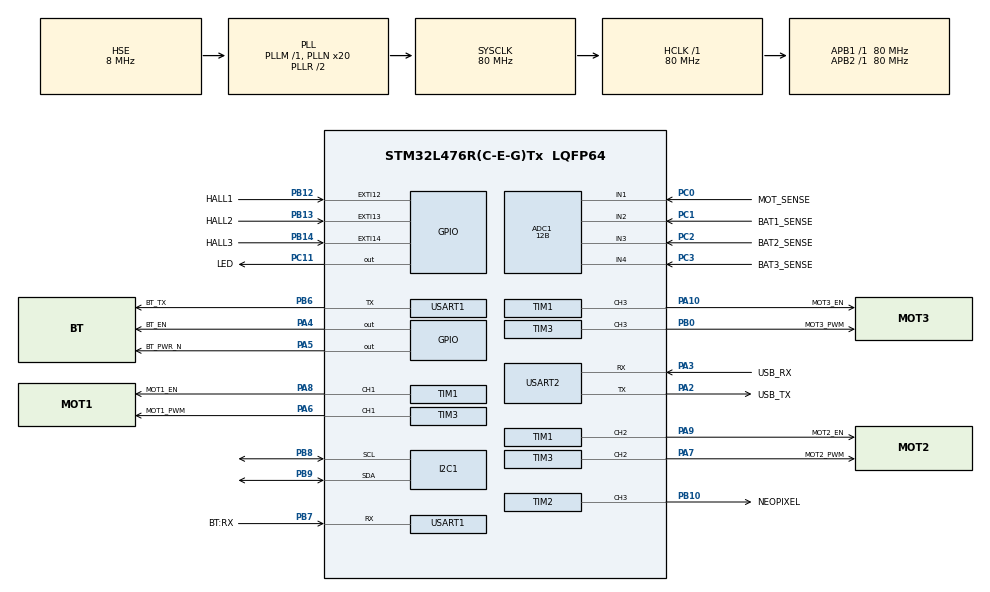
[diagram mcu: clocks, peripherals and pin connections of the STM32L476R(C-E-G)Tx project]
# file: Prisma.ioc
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ADC1.Channel-0\#ChannelRegularConversion=ADC_CHANNEL_1
ADC1.Channel-1\#ChannelRegularConversion=ADC_CHANNEL_2
ADC1.Channel-2\#ChannelRegularConversion=ADC_CHANNEL_3
ADC1.Channel-3\#ChannelRegularConversion=ADC_CHANNEL_4
ADC1.ClockPrescaler=ADC_CLOCK_ASYNC_DIV128
ADC1.ContinuousConvMode=ENABLE
ADC1.DMAContinuousRequests=DISABLE
ADC1.EOCSelection=ADC_EOC_SEQ_CONV
ADC1.NbrOfConversion=4
ADC1.NbrOfConversionFlag=1
ADC1.OffsetNumber-0\#ChannelRegularConversion=ADC_OFFSET_NONE
ADC1.OffsetNumber-1\#ChannelRegularConversion=ADC_OFFSET_NONE
ADC1.OffsetNumber-2\#ChannelRegularConversion=ADC_OFFSET_NONE
ADC1.OffsetNumber-3\#ChannelRegularConversion=ADC_OFFSET_NONE
ADC1.Rank-0\#ChannelRegularConversion=1
ADC1.Rank-1\#ChannelRegularConversion=2
ADC1.Rank-2\#ChannelRegularConversion=3
ADC1.Rank-3\#ChannelRegularConversion=4
ADC1.Resolution=ADC_RESOLUTION_12B
ADC1.SamplingTime-0\#ChannelRegularConversion=ADC_SAMPLETIME_2CYCLES_5
ADC1.SamplingTime-1\#ChannelRegularConversion=ADC_SAMPLETIME_2CYCLES_5
ADC1.SamplingTime-2\#ChannelRegularConversion=ADC_SAMPLETIME_2CYCLES_5
ADC1.SamplingTime-3\#ChannelRegularConversion=ADC_SAMPLETIME_2CYCLES_5
ADC1.master=1
Dma.ADC1.0.Direction=DMA_PERIPH_TO_MEMORY
Dma.ADC1.0.Instance=DMA2_Channel3
Dma.ADC1.0.MemDataAlignment=DMA_MDATAALIGN_HALFWORD
Dma.ADC1.0.MemInc=DMA_MINC_ENABLE
Dma.ADC1.0.Mode=DMA_CIRCULAR
Dma.ADC1.0.PeriphDataAlignment=DMA_PDATAALIGN_HALFWORD
Dma.ADC1.0.PeriphInc=DMA_PINC_DISABLE
Dma.ADC1.0.Priority=DMA_PRIORITY_LOW
Dma.Request0=ADC1
Dma.Request1=TIM2_CH3
Dma.TIM2_CH3.1.Direction=DMA_MEMORY_TO_PERIPH
Dma.TIM2_CH3.1.Instance=DMA1_Channel1
Dma.TIM2_CH3.1.MemDataAlignment=DMA_MDATAALIGN_HALFWORD
Dma.TIM2_CH3.1.MemInc=DMA_MINC_ENABLE
Dma.TIM2_CH3.1.Mode=DMA_NORMAL
Dma.TIM2_CH3.1.PeriphDataAlignment=DMA_PDATAALIGN_WORD
Dma.TIM2_CH3.1.PeriphInc=DMA_PINC_DISABLE
Dma.TIM2_CH3.1.Priority=DMA_PRIORITY_LOW
I2C1.Timing=0x10909CEC
Mcu.Family=STM32L4
Mcu.Name=STM32L476R(C-E-G)Tx
Mcu.Package=LQFP64
NVIC.DMA1_Channel1_IRQn=true\:0\:0\:false\:false\:true\:false\:true\:true
NVIC.DMA2_Channel3_IRQn=true\:0\:0\:false\:false\:true\:false\:true\:true
NVIC.EXTI15_10_IRQn=true\:2\:0\:true\:false\:false\:true\:false\:true
NVIC.PriorityGroup=NVIC_PRIORITYGROUP_4
NVIC.TIM4_IRQn=true\:0\:0\:false\:false\:false\:true\:false\:true
NVIC.TIM7_IRQn=true\:0\:0\:false\:false\:false\:true\:false\:true
NVIC.USART1_IRQn=true\:0\:0\:false\:false\:false\:true\:false\:true
NVIC.USART2_IRQn=true\:0\:0\:false\:false\:false\:true\:false\:true
PA10.GPIO_Label=MOT3_EN
PA10.GPIO_PuPd=GPIO_PULLDOWN
PA10.Signal=S_TIM1_CH3
PA13\ (JTMS-SWDIO).Mode=Serial_Wire
PA13\ (JTMS-SWDIO).Signal=SYS_JTMS-SWDIO
PA14\ (JTCK-SWCLK).Mode=Serial_Wire
PA14\ (JTCK-SWCLK).Signal=SYS_JTCK-SWCLK
PA2.GPIO_Label=USB_TX
PA2.Mode=Asynchronous
PA2.Signal=USART2_TX
PA3.GPIO_Label=USB_RX
PA3.Mode=Asynchronous
PA3.Signal=USART2_RX
PA4.GPIO_Label=BT_EN
PA4.Signal=GPIO_Output
PA5.GPIO_Label=BT_PWR_N
PA5.PinState=GPIO_PIN_SET
PA5.Signal=GPIO_Output
PA6.GPIO_Label=MOT1_PWM
PA6.GPIO_PuPd=GPIO_PULLDOWN
PA6.Signal=S_TIM3_CH1
PA7.GPIO_Label=MOT2_PWM
PA7.GPIO_PuPd=GPIO_PULLDOWN
PA7.Signal=S_TIM3_CH2
PA8.GPIO_Label=MOT1_EN
PA8.GPIO_PuPd=GPIO_PULLDOWN
PA8.Signal=S_TIM1_CH1
PA9.GPIO_Label=MOT2_EN
PA9.GPIO_PuPd=GPIO_PULLDOWN
PA9.Signal=S_TIM1_CH2
PB0.GPIO_Label=MOT3_PWM
PB0.GPIO_PuPd=GPIO_PULLDOWN
PB0.Signal=S_TIM3_CH3
PB10.GPIO_Label=NEOPIXEL
PB10.Signal=S_TIM2_CH3
PB12.GPIO_Label=HALL1
PB12.GPIO_ModeDefaultEXTI=GPIO_MODE_IT_RISING_FALLING
PB12.GPIO_PuPd=GPIO_PULLDOWN
PB12.Signal=GPXTI12
PB13.GPIO_Label=HALL2
PB13.GPIO_ModeDefaultEXTI=GPIO_MODE_IT_RISING_FALLING
PB13.GPIO_PuPd=GPIO_PULLDOWN
PB13.Signal=GPXTI13
PB14.GPIO_Label=HALL3
PB14.GPIO_ModeDefaultEXTI=GPIO_MODE_IT_RISING_FALLING
PB14.GPIO_PuPd=GPIO_PULLDOWN
PB14.Signal=GPXTI14
PB6.GPIO_Label=BT_TX
PB6.Mode=Asynchronous
PB6.Signal=USART1_TX
PB7.GPIO_Label=BT\:RX
PB7.Mode=Asynchronous
PB7.Signal=USART1_RX
PB8.Mode=I2C
PB8.Signal=I2C1_SCL
PB9.Mode=I2C
PB9.Signal=I2C1_SDA
PC0.GPIO_Label=MOT_SENSE
PC0.Signal=ADCx_IN1
PC1.GPIO_Label=BAT1_SENSE
PC1.Signal=ADCx_IN2
PC11.GPIO_Label=LED
PC11.PinState=GPIO_PIN_SET
PC11.Signal=GPIO_Output
PC2.GPIO_Label=BAT2_SENSE
PC2.Signal=ADCx_IN3
PC3.GPIO_Label=BAT3_SENSE
PC3.Signal=ADCx_IN4
PH0-OSC_IN\ (PH0).Mode=HSE-External-Oscillator
PH0-OSC_IN\ (PH0).Signal=RCC_OSC_IN
PH1-OSC_OUT\ (PH1).Mode=HSE-External-Oscillator
PH1-OSC_OUT\ (PH1).Signal=RCC_OSC_OUT
ProjectManager.HeapSize=0x200
ProjectManager.StackSize=0x400
ProjectManager.TargetToolchain=STM32CubeIDE
RCC.ADCFreq_Value=32000000
RCC.AHBFreq_Value=80000000
RCC.APB1Freq_Value=80000000
RCC.APB1TimFreq_Value=80000000
RCC.APB2Freq_Value=80000000
RCC.APB2TimFreq_Value=80000000
RCC.CortexFreq_Value=80000000
RCC.HCLKFreq_Value=80000000
RCC.HSE_VALUE=8000000
RCC.HSI_VALUE=16000000
RCC.LSE_VALUE=32768
RCC.MSI_VALUE=4000000
RCC.PLLN=20
RCC.PLLSourceVirtual=RCC_PLLSOURCE_HSE
RCC.SYSCLKFreq_VALUE=80000000
RCC.SYSCLKSource=RCC_SYSCLKSOURCE_PLLCLK
RCC.USBFreq_Value=32000000
RCC.VCOOutputFreq_Value=160000000
SH.ADCx_IN1.0=ADC1_IN1,IN1-Single-Ended
SH.ADCx_IN2.0=ADC1_IN2,IN2-Single-Ended
SH.ADCx_IN3.0=ADC1_IN3,IN3-Single-Ended
SH.ADCx_IN4.0=ADC1_IN4,IN4-Single-Ended
SH.S_TIM1_CH1.0=TIM1_CH1,PWM Generation1 CH1
SH.S_TIM1_CH2.0=TIM1_CH2,PWM Generation2 CH2
SH.S_TIM1_CH3.0=TIM1_CH3,PWM Generation3 CH3
SH.S_TIM2_CH3.0=TIM2_CH3,PWM Generation3 CH3
SH.S_TIM3_CH1.0=TIM3_CH1,PWM Generation1 CH1
SH.S_TIM3_CH2.0=TIM3_CH2,PWM Generation2 CH2
SH.S_TIM3_CH3.0=TIM3_CH3,PWM Generation3 CH3
TIM1.Channel-PWM\ Generation1\ CH1=TIM_CHANNEL_1
TIM1.Channel-PWM\ Generation2\ CH2=TIM_CHANNEL_2
TIM1.Channel-PWM\ Generation3\ CH3=TIM_CHANNEL_3
TIM1.Period=100
TIM1.Prescaler=79
TIM2.Channel-PWM\ Generation3\ CH3=TIM_CHANNEL_3
TIM2.Period=100
TIM3.Channel-PWM\ Generation1\ CH1=TIM_CHANNEL_1
TIM3.Channel-PWM\ Generation2\ CH2=TIM_CHANNEL_2
TIM3.Channel-PWM\ Generation3\ CH3=TIM_CHANNEL_3
TIM3.Period=100
TIM3.Prescaler=79
TIM4.AutoReloadPreload=TIM_AUTORELOAD_PRELOAD_DISABLE
TIM4.Period=999
TIM4.Prescaler=7999
TIM5.Prescaler=79
TIM7.Period=9999
TIM7.Prescaler=79
USART1.DMADisableonRxErrorParam=ADVFEATURE_DMA_DISABLEONRXERROR
USART1.SwapParam=ADVFEATURE_SWAP_ENABLE
USART1.VirtualMode-Asynchronous=VM_ASYNC
USART2.VirtualMode-Asynchronous=VM_ASYNC
VP_TIM1_VS_ClockSourceINT.Mode=Internal
VP_TIM2_VS_ClockSourceINT.Mode=Internal
VP_TIM3_VS_ClockSourceINT.Mode=Internal
VP_TIM4_VS_ClockSourceINT.Mode=Internal
VP_TIM5_VS_ClockSourceINT.Mode=Internal
VP_TIM7_VS_ClockSourceINT.Mode=Enable_Timer
board=custom

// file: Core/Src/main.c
/* USER CODE BEGIN Header */
/**
  ******************************************************************************
  * @file           : main.c
  * @brief          : Main program body
  ******************************************************************************
  * @attention
  *
  * Copyright (c) 2023 STMicroelectronics.
  * All rights reserved.
  *
  * This software is licensed under terms that can be found in the LICENSE file
  * in the root directory of this software component.
  * If no LICENSE file comes with this software, it is provided AS-IS.
  *
  ******************************************************************************
  */
/* USER CODE END Header */
#include "main.h"

ADC_HandleTypeDef hadc1;
DMA_HandleTypeDef hdma_adc1;

I2C_HandleTypeDef hi2c1;

TIM_HandleTypeDef htim1;
TIM_HandleTypeDef htim2;
TIM_HandleTypeDef htim3;
TIM_HandleTypeDef htim4;
TIM_HandleTypeDef htim5;
TIM_HandleTypeDef htim7;
DMA_HandleTypeDef hdma_tim2_ch3;

UART_HandleTypeDef huart1;
UART_HandleTypeDef huart2;

void SystemClock_Config(void);
static void MX_GPIO_Init(void);
static void MX_DMA_Init(void);
static void MX_USART2_UART_Init(void);
static void MX_USART1_UART_Init(void);
static void MX_TIM1_Init(void);
static void MX_TIM3_Init(void);
static void MX_ADC1_Init(void);
static void MX_TIM2_Init(void);
static void MX_TIM4_Init(void);
static void MX_TIM5_Init(void);
static void MX_TIM7_Init(void);
static void MX_I2C1_Init(void);
/* USER CODE BEGIN PFP */
void main_user();

/* USER CODE END PFP */

int main(void)
{

  /* MCU Configuration--------------------------------------------------------*/

  /* Reset of all peripherals, Initializes the Flash interface and the Systick. */
  HAL_Init();

  /* Configure the system clock */
  SystemClock_Config();

  /* Initialize all configured peripherals */
  MX_GPIO_Init();
  MX_DMA_Init();
  MX_USART2_UART_Init();
  MX_USART1_UART_Init();
  MX_TIM1_Init();
  MX_TIM3_Init();
  MX_ADC1_Init();
  MX_TIM2_Init();
  MX_TIM4_Init();
  MX_TIM5_Init();
  MX_TIM7_Init();
  MX_I2C1_Init();
  /* USER CODE BEGIN 2 */
  main_user();
  /* USER CODE END 2 */

  /* Infinite loop */
  while (1)
  {

  }
}

void SystemClock_Config(void)
{
  RCC_OscInitTypeDef RCC_OscInitStruct = {0};
  RCC_ClkInitTypeDef RCC_ClkInitStruct = {0};

  /** Configure the main internal regulator output voltage
  */
  if (HAL_PWREx_ControlVoltageScaling(PWR_REGULATOR_VOLTAGE_SCALE1) != HAL_OK)
  {
    Error_Handler();
  }

  /** Initializes the RCC Oscillators according to the specified parameters
  * in the RCC_OscInitTypeDef structure.
  */
  RCC_OscInitStruct.OscillatorType = RCC_OSCILLATORTYPE_HSE;
  RCC_OscInitStruct.HSEState = RCC_HSE_ON;
  RCC_OscInitStruct.PLL.PLLState = RCC_PLL_ON;
  RCC_OscInitStruct.PLL.PLLSource = RCC_PLLSOURCE_HSE;
  RCC_OscInitStruct.PLL.PLLM = 1;
  RCC_OscInitStruct.PLL.PLLN = 20;
  RCC_OscInitStruct.PLL.PLLP = RCC_PLLP_DIV7;
  RCC_OscInitStruct.PLL.PLLQ = RCC_PLLQ_DIV2;
  RCC_OscInitStruct.PLL.PLLR = RCC_PLLR_DIV2;
  if (HAL_RCC_OscConfig(&RCC_OscInitStruct) != HAL_OK)
  {
    Error_Handler();
  }

  /** Initializes the CPU, AHB and APB buses clocks
  */
  RCC_ClkInitStruct.ClockType = RCC_CLOCKTYPE_HCLK|RCC_CLOCKTYPE_SYSCLK
                              |RCC_CLOCKTYPE_PCLK1|RCC_CLOCKTYPE_PCLK2;
  RCC_ClkInitStruct.SYSCLKSource = RCC_SYSCLKSOURCE_PLLCLK;
  RCC_ClkInitStruct.AHBCLKDivider = RCC_SYSCLK_DIV1;
  RCC_ClkInitStruct.APB1CLKDivider = RCC_HCLK_DIV1;
  RCC_ClkInitStruct.APB2CLKDivider = RCC_HCLK_DIV1;

  if (HAL_RCC_ClockConfig(&RCC_ClkInitStruct, FLASH_LATENCY_4) != HAL_OK)
  {
    Error_Handler();
  }
}

static void MX_ADC1_Init(void)
{

  ADC_MultiModeTypeDef multimode = {0};
  ADC_ChannelConfTypeDef sConfig = {0};

  /** Common config
  */
  hadc1.Instance = ADC1;
  hadc1.Init.ClockPrescaler = ADC_CLOCK_ASYNC_DIV128;
  hadc1.Init.Resolution = ADC_RESOLUTION_12B;
  hadc1.Init.DataAlign = ADC_DATAALIGN_RIGHT;
  hadc1.Init.ScanConvMode = ADC_SCAN_ENABLE;
  hadc1.Init.EOCSelection = ADC_EOC_SEQ_CONV;
  hadc1.Init.LowPowerAutoWait = DISABLE;
  hadc1.Init.ContinuousConvMode = ENABLE;
  hadc1.Init.NbrOfConversion = 4;
  hadc1.Init.DiscontinuousConvMode = DISABLE;
  hadc1.Init.ExternalTrigConv = ADC_SOFTWARE_START;
  hadc1.Init.ExternalTrigConvEdge = ADC_EXTERNALTRIGCONVEDGE_NONE;
  hadc1.Init.DMAContinuousRequests = DISABLE;
  hadc1.Init.Overrun = ADC_OVR_DATA_PRESERVED;
  hadc1.Init.OversamplingMode = DISABLE;
  if (HAL_ADC_Init(&hadc1) != HAL_OK)
  {
    Error_Handler();
  }

  /** Configure the ADC multi-mode
  */
  multimode.Mode = ADC_MODE_INDEPENDENT;
  if (HAL_ADCEx_MultiModeConfigChannel(&hadc1, &multimode) != HAL_OK)
  {
    Error_Handler();
  }

  /** Configure Regular Channel
  */
  sConfig.Channel = ADC_CHANNEL_1;
  sConfig.Rank = ADC_REGULAR_RANK_1;
  sConfig.SamplingTime = ADC_SAMPLETIME_2CYCLES_5;
  sConfig.SingleDiff = ADC_SINGLE_ENDED;
  sConfig.OffsetNumber = ADC_OFFSET_NONE;
  sConfig.Offset = 0;
  if (HAL_ADC_ConfigChannel(&hadc1, &sConfig) != HAL_OK)
  {
    Error_Handler();
  }

  /** Configure Regular Channel
  */
  sConfig.Channel = ADC_CHANNEL_2;
  sConfig.Rank = ADC_REGULAR_RANK_2;
  if (HAL_ADC_ConfigChannel(&hadc1, &sConfig) != HAL_OK)
  {
    Error_Handler();
  }

  /** Configure Regular Channel
  */
  sConfig.Channel = ADC_CHANNEL_3;
  sConfig.Rank = ADC_REGULAR_RANK_3;
  if (HAL_ADC_ConfigChannel(&hadc1, &sConfig) != HAL_OK)
  {
    Error_Handler();
  }

  /** Configure Regular Channel
  */
  sConfig.Channel = ADC_CHANNEL_4;
  sConfig.Rank = ADC_REGULAR_RANK_4;
  if (HAL_ADC_ConfigChannel(&hadc1, &sConfig) != HAL_OK)
  {
    Error_Handler();
  }

}

static void MX_I2C1_Init(void)
{

  hi2c1.Instance = I2C1;
  hi2c1.Init.Timing = 0x10909CEC;
  hi2c1.Init.OwnAddress1 = 0;
  hi2c1.Init.AddressingMode = I2C_ADDRESSINGMODE_7BIT;
  hi2c1.Init.DualAddressMode = I2C_DUALADDRESS_DISABLE;
  hi2c1.Init.OwnAddress2 = 0;
  hi2c1.Init.OwnAddress2Masks = I2C_OA2_NOMASK;
  hi2c1.Init.GeneralCallMode = I2C_GENERALCALL_DISABLE;
  hi2c1.Init.NoStretchMode = I2C_NOSTRETCH_DISABLE;
  if (HAL_I2C_Init(&hi2c1) != HAL_OK)
  {
    Error_Handler();
  }

  /** Configure Analogue filter
  */
  if (HAL_I2CEx_ConfigAnalogFilter(&hi2c1, I2C_ANALOGFILTER_ENABLE) != HAL_OK)
  {
    Error_Handler();
  }

  /** Configure Digital filter
  */
  if (HAL_I2CEx_ConfigDigitalFilter(&hi2c1, 0) != HAL_OK)
  {
    Error_Handler();
  }

}

static void MX_TIM1_Init(void)
{

  TIM_ClockConfigTypeDef sClockSourceConfig = {0};
  TIM_MasterConfigTypeDef sMasterConfig = {0};
  TIM_OC_InitTypeDef sConfigOC = {0};
  TIM_BreakDeadTimeConfigTypeDef sBreakDeadTimeConfig = {0};

  htim1.Instance = TIM1;
  htim1.Init.Prescaler = 79;
  htim1.Init.CounterMode = TIM_COUNTERMODE_UP;
  htim1.Init.Period = 100;
  htim1.Init.ClockDivision = TIM_CLOCKDIVISION_DIV1;
  htim1.Init.RepetitionCounter = 0;
  htim1.Init.AutoReloadPreload = TIM_AUTORELOAD_PRELOAD_DISABLE;
  if (HAL_TIM_Base_Init(&htim1) != HAL_OK)
  {
    Error_Handler();
  }
  sClockSourceConfig.ClockSource = TIM_CLOCKSOURCE_INTERNAL;
  if (HAL_TIM_ConfigClockSource(&htim1, &sClockSourceConfig) != HAL_OK)
  {
    Error_Handler();
  }
  if (HAL_TIM_PWM_Init(&htim1) != HAL_OK)
  {
    Error_Handler();
  }
  sMasterConfig.MasterOutputTrigger = TIM_TRGO_RESET;
  sMasterConfig.MasterOutputTrigger2 = TIM_TRGO2_RESET;
  sMasterConfig.MasterSlaveMode = TIM_MASTERSLAVEMODE_DISABLE;
  if (HAL_TIMEx_MasterConfigSynchronization(&htim1, &sMasterConfig) != HAL_OK)
  {
    Error_Handler();
  }
  sConfigOC.OCMode = TIM_OCMODE_PWM1;
  sConfigOC.Pulse = 0;
  sConfigOC.OCPolarity = TIM_OCPOLARITY_HIGH;
  sConfigOC.OCNPolarity = TIM_OCNPOLARITY_HIGH;
  sConfigOC.OCFastMode = TIM_OCFAST_DISABLE;
  sConfigOC.OCIdleState = TIM_OCIDLESTATE_RESET;
  sConfigOC.OCNIdleState = TIM_OCNIDLESTATE_RESET;
  if (HAL_TIM_PWM_ConfigChannel(&htim1, &sConfigOC, TIM_CHANNEL_1) != HAL_OK)
  {
    Error_Handler();
  }
  if (HAL_TIM_PWM_ConfigChannel(&htim1, &sConfigOC, TIM_CHANNEL_2) != HAL_OK)
  {
    Error_Handler();
  }
  if (HAL_TIM_PWM_ConfigChannel(&htim1, &sConfigOC, TIM_CHANNEL_3) != HAL_OK)
  {
    Error_Handler();
  }
  sBreakDeadTimeConfig.OffStateRunMode = TIM_OSSR_DISABLE;
  sBreakDeadTimeConfig.OffStateIDLEMode = TIM_OSSI_DISABLE;
  sBreakDeadTimeConfig.LockLevel = TIM_LOCKLEVEL_OFF;
  sBreakDeadTimeConfig.DeadTime = 0;
  sBreakDeadTimeConfig.BreakState = TIM_BREAK_DISABLE;
  sBreakDeadTimeConfig.BreakPolarity = TIM_BREAKPOLARITY_HIGH;
  sBreakDeadTimeConfig.BreakFilter = 0;
  sBreakDeadTimeConfig.Break2State = TIM_BREAK2_DISABLE;
  sBreakDeadTimeConfig.Break2Polarity = TIM_BREAK2POLARITY_HIGH;
  sBreakDeadTimeConfig.Break2Filter = 0;
  sBreakDeadTimeConfig.AutomaticOutput = TIM_AUTOMATICOUTPUT_DISABLE;
  if (HAL_TIMEx_ConfigBreakDeadTime(&htim1, &sBreakDeadTimeConfig) != HAL_OK)
  {
    Error_Handler();
  }
  HAL_TIM_MspPostInit(&htim1);

}

static void MX_TIM2_Init(void)
{

  TIM_ClockConfigTypeDef sClockSourceConfig = {0};
  TIM_MasterConfigTypeDef sMasterConfig = {0};
  TIM_OC_InitTypeDef sConfigOC = {0};

  htim2.Instance = TIM2;
  htim2.Init.Prescaler = 0;
  htim2.Init.CounterMode = TIM_COUNTERMODE_UP;
  htim2.Init.Period = 100;
  htim2.Init.ClockDivision = TIM_CLOCKDIVISION_DIV1;
  htim2.Init.AutoReloadPreload = TIM_AUTORELOAD_PRELOAD_DISABLE;
  if (HAL_TIM_Base_Init(&htim2) != HAL_OK)
  {
    Error_Handler();
  }
  sClockSourceConfig.ClockSource = TIM_CLOCKSOURCE_INTERNAL;
  if (HAL_TIM_ConfigClockSource(&htim2, &sClockSourceConfig) != HAL_OK)
  {
    Error_Handler();
  }
  if (HAL_TIM_PWM_Init(&htim2) != HAL_OK)
  {
    Error_Handler();
  }
  sMasterConfig.MasterOutputTrigger = TIM_TRGO_RESET;
  sMasterConfig.MasterSlaveMode = TIM_MASTERSLAVEMODE_DISABLE;
  if (HAL_TIMEx_MasterConfigSynchronization(&htim2, &sMasterConfig) != HAL_OK)
  {
    Error_Handler();
  }
  sConfigOC.OCMode = TIM_OCMODE_PWM1;
  sConfigOC.Pulse = 0;
  sConfigOC.OCPolarity = TIM_OCPOLARITY_HIGH;
  sConfigOC.OCFastMode = TIM_OCFAST_DISABLE;
  if (HAL_TIM_PWM_ConfigChannel(&htim2, &sConfigOC, TIM_CHANNEL_3) != HAL_OK)
  {
    Error_Handler();
  }
  HAL_TIM_MspPostInit(&htim2);

}

static void MX_TIM3_Init(void)
{

  TIM_ClockConfigTypeDef sClockSourceConfig = {0};
  TIM_MasterConfigTypeDef sMasterConfig = {0};
  TIM_OC_InitTypeDef sConfigOC = {0};

  htim3.Instance = TIM3;
  htim3.Init.Prescaler = 79;
  htim3.Init.CounterMode = TIM_COUNTERMODE_UP;
  htim3.Init.Period = 100;
  htim3.Init.ClockDivision = TIM_CLOCKDIVISION_DIV1;
  htim3.Init.AutoReloadPreload = TIM_AUTORELOAD_PRELOAD_DISABLE;
  if (HAL_TIM_Base_Init(&htim3) != HAL_OK)
  {
    Error_Handler();
  }
  sClockSourceConfig.ClockSource = TIM_CLOCKSOURCE_INTERNAL;
  if (HAL_TIM_ConfigClockSource(&htim3, &sClockSourceConfig) != HAL_OK)
  {
    Error_Handler();
  }
  if (HAL_TIM_PWM_Init(&htim3) != HAL_OK)
  {
    Error_Handler();
  }
  sMasterConfig.MasterOutputTrigger = TIM_TRGO_RESET;
  sMasterConfig.MasterSlaveMode = TIM_MASTERSLAVEMODE_DISABLE;
  if (HAL_TIMEx_MasterConfigSynchronization(&htim3, &sMasterConfig) != HAL_OK)
  {
    Error_Handler();
  }
  sConfigOC.OCMode = TIM_OCMODE_PWM1;
  sConfigOC.Pulse = 0;
  sConfigOC.OCPolarity = TIM_OCPOLARITY_HIGH;
  sConfigOC.OCFastMode = TIM_OCFAST_DISABLE;
  if (HAL_TIM_PWM_ConfigChannel(&htim3, &sConfigOC, TIM_CHANNEL_1) != HAL_OK)
  {
    Error_Handler();
  }
  if (HAL_TIM_PWM_ConfigChannel(&htim3, &sConfigOC, TIM_CHANNEL_2) != HAL_OK)
  {
    Error_Handler();
  }
  if (HAL_TIM_PWM_ConfigChannel(&htim3, &sConfigOC, TIM_CHANNEL_3) != HAL_OK)
  {
    Error_Handler();
  }
  HAL_TIM_MspPostInit(&htim3);

}

static void MX_TIM4_Init(void)
{

  TIM_ClockConfigTypeDef sClockSourceConfig = {0};
  TIM_MasterConfigTypeDef sMasterConfig = {0};

  htim4.Instance = TIM4;
  htim4.Init.Prescaler = 7999;
  htim4.Init.CounterMode = TIM_COUNTERMODE_UP;
  htim4.Init.Period = 999;
  htim4.Init.ClockDivision = TIM_CLOCKDIVISION_DIV1;
  htim4.Init.AutoReloadPreload = TIM_AUTORELOAD_PRELOAD_DISABLE;
  if (HAL_TIM_Base_Init(&htim4) != HAL_OK)
  {
    Error_Handler();
  }
  sClockSourceConfig.ClockSource = TIM_CLOCKSOURCE_INTERNAL;
  if (HAL_TIM_ConfigClockSource(&htim4, &sClockSourceConfig) != HAL_OK)
  {
    Error_Handler();
  }
  sMasterConfig.MasterOutputTrigger = TIM_TRGO_RESET;
  sMasterConfig.MasterSlaveMode = TIM_MASTERSLAVEMODE_DISABLE;
  if (HAL_TIMEx_MasterConfigSynchronization(&htim4, &sMasterConfig) != HAL_OK)
  {
    Error_Handler();
  }

}

static void MX_TIM5_Init(void)
{

  TIM_ClockConfigTypeDef sClockSourceConfig = {0};
  TIM_MasterConfigTypeDef sMasterConfig = {0};

  htim5.Instance = TIM5;
  htim5.Init.Prescaler = 79;
  htim5.Init.CounterMode = TIM_COUNTERMODE_UP;
  htim5.Init.Period = 4294967295;
  htim5.Init.ClockDivision = TIM_CLOCKDIVISION_DIV1;
  htim5.Init.AutoReloadPreload = TIM_AUTORELOAD_PRELOAD_DISABLE;
  if (HAL_TIM_Base_Init(&htim5) != HAL_OK)
  {
    Error_Handler();
  }
  sClockSourceConfig.ClockSource = TIM_CLOCKSOURCE_INTERNAL;
  if (HAL_TIM_ConfigClockSource(&htim5, &sClockSourceConfig) != HAL_OK)
  {
    Error_Handler();
  }
  sMasterConfig.MasterOutputTrigger = TIM_TRGO_RESET;
  sMasterConfig.MasterSlaveMode = TIM_MASTERSLAVEMODE_DISABLE;
  if (HAL_TIMEx_MasterConfigSynchronization(&htim5, &sMasterConfig) != HAL_OK)
  {
    Error_Handler();
  }

}

static void MX_TIM7_Init(void)
{

  TIM_MasterConfigTypeDef sMasterConfig = {0};

  htim7.Instance = TIM7;
  htim7.Init.Prescaler = 79;
  htim7.Init.CounterMode = TIM_COUNTERMODE_UP;
  htim7.Init.Period = 9999;
  htim7.Init.AutoReloadPreload = TIM_AUTORELOAD_PRELOAD_DISABLE;
  if (HAL_TIM_Base_Init(&htim7) != HAL_OK)
  {
    Error_Handler();
  }
  sMasterConfig.MasterOutputTrigger = TIM_TRGO_RESET;
  sMasterConfig.MasterSlaveMode = TIM_MASTERSLAVEMODE_DISABLE;
  if (HAL_TIMEx_MasterConfigSynchronization(&htim7, &sMasterConfig) != HAL_OK)
  {
    Error_Handler();
  }

}

static void MX_USART1_UART_Init(void)
{

  huart1.Instance = USART1;
  huart1.Init.BaudRate = 115200;
  huart1.Init.WordLength = UART_WORDLENGTH_8B;
  huart1.Init.StopBits = UART_STOPBITS_1;
  huart1.Init.Parity = UART_PARITY_NONE;
  huart1.Init.Mode = UART_MODE_TX_RX;
  huart1.Init.HwFlowCtl = UART_HWCONTROL_NONE;
  huart1.Init.OverSampling = UART_OVERSAMPLING_16;
  huart1.Init.OneBitSampling = UART_ONE_BIT_SAMPLE_DISABLE;
  huart1.AdvancedInit.AdvFeatureInit = UART_ADVFEATURE_SWAP_INIT|UART_ADVFEATURE_DMADISABLEONERROR_INIT;
  huart1.AdvancedInit.Swap = UART_ADVFEATURE_SWAP_ENABLE;
  huart1.AdvancedInit.DMADisableonRxError = UART_ADVFEATURE_DMA_DISABLEONRXERROR;
  if (HAL_UART_Init(&huart1) != HAL_OK)
  {
    Error_Handler();
  }

}

static void MX_USART2_UART_Init(void)
{

  huart2.Instance = USART2;
  huart2.Init.BaudRate = 115200;
  huart2.Init.WordLength = UART_WORDLENGTH_8B;
  huart2.Init.StopBits = UART_STOPBITS_1;
  huart2.Init.Parity = UART_PARITY_NONE;
  huart2.Init.Mode = UART_MODE_TX_RX;
  huart2.Init.HwFlowCtl = UART_HWCONTROL_NONE;
  huart2.Init.OverSampling = UART_OVERSAMPLING_16;
  huart2.Init.OneBitSampling = UART_ONE_BIT_SAMPLE_DISABLE;
  huart2.AdvancedInit.AdvFeatureInit = UART_ADVFEATURE_NO_INIT;
  if (HAL_UART_Init(&huart2) != HAL_OK)
  {
    Error_Handler();
  }

}

static void MX_DMA_Init(void)
{

  /* DMA controller clock enable */
  __HAL_RCC_DMA2_CLK_ENABLE();
  __HAL_RCC_DMA1_CLK_ENABLE();

  /* DMA interrupt init */
  /* DMA1_Channel1_IRQn interrupt configuration */
  HAL_NVIC_SetPriority(DMA1_Channel1_IRQn, 0, 0);
  HAL_NVIC_EnableIRQ(DMA1_Channel1_IRQn);
  /* DMA2_Channel3_IRQn interrupt configuration */
  HAL_NVIC_SetPriority(DMA2_Channel3_IRQn, 0, 0);
  HAL_NVIC_EnableIRQ(DMA2_Channel3_IRQn);

}

static void MX_GPIO_Init(void)
{
  GPIO_InitTypeDef GPIO_InitStruct = {0};

  /* GPIO Ports Clock Enable */
  __HAL_RCC_GPIOH_CLK_ENABLE();
  __HAL_RCC_GPIOC_CLK_ENABLE();
  __HAL_RCC_GPIOA_CLK_ENABLE();
  __HAL_RCC_GPIOB_CLK_ENABLE();

  /*Configure GPIO pin Output Level */
  HAL_GPIO_WritePin(BT_EN_GPIO_Port, BT_EN_Pin, GPIO_PIN_RESET);

  /*Configure GPIO pin Output Level */
  HAL_GPIO_WritePin(BT_PWR_N_GPIO_Port, BT_PWR_N_Pin, GPIO_PIN_SET);

  /*Configure GPIO pin Output Level */
  HAL_GPIO_WritePin(LED_GPIO_Port, LED_Pin, GPIO_PIN_SET);

  /*Configure GPIO pins : BT_EN_Pin BT_PWR_N_Pin */
  GPIO_InitStruct.Pin = BT_EN_Pin|BT_PWR_N_Pin;
  GPIO_InitStruct.Mode = GPIO_MODE_OUTPUT_PP;
  GPIO_InitStruct.Pull = GPIO_NOPULL;
  GPIO_InitStruct.Speed = GPIO_SPEED_FREQ_LOW;
  HAL_GPIO_Init(GPIOA, &GPIO_InitStruct);

  /*Configure GPIO pins : HALL1_Pin HALL2_Pin HALL3_Pin */
  GPIO_InitStruct.Pin = HALL1_Pin|HALL2_Pin|HALL3_Pin;
  GPIO_InitStruct.Mode = GPIO_MODE_IT_RISING_FALLING;
  GPIO_InitStruct.Pull = GPIO_PULLDOWN;
  HAL_GPIO_Init(GPIOB, &GPIO_InitStruct);

  /*Configure GPIO pin : LED_Pin */
  GPIO_InitStruct.Pin = LED_Pin;
  GPIO_InitStruct.Mode = GPIO_MODE_OUTPUT_PP;
  GPIO_InitStruct.Pull = GPIO_NOPULL;
  GPIO_InitStruct.Speed = GPIO_SPEED_FREQ_LOW;
  HAL_GPIO_Init(LED_GPIO_Port, &GPIO_InitStruct);

  /* EXTI interrupt init*/
  HAL_NVIC_SetPriority(EXTI15_10_IRQn, 2, 0);
  HAL_NVIC_EnableIRQ(EXTI15_10_IRQn);

}

void Error_Handler(void)
{
  __disable_irq();
  while (1)
  {
  }
}
